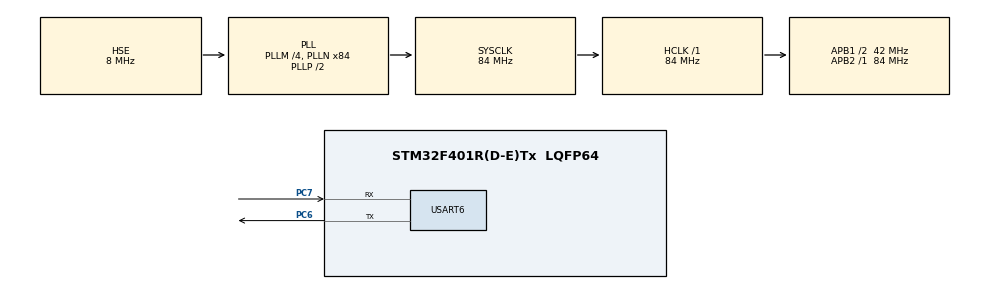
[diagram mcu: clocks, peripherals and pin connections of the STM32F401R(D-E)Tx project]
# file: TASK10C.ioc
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Mcu.Family=STM32F4
Mcu.Name=STM32F401R(D-E)Tx
Mcu.Package=LQFP64
NVIC.PriorityGroup=NVIC_PRIORITYGROUP_4
PC6.Mode=Asynchronous
PC6.Signal=USART6_TX
PC7.Mode=Asynchronous
PC7.Signal=USART6_RX
PH0\ -\ OSC_IN.Mode=HSE-External-Clock-Source
PH0\ -\ OSC_IN.Signal=RCC_OSC_IN
PH1\ -\ OSC_OUT.Mode=HSE-External-Clock-Source
PH1\ -\ OSC_OUT.Signal=RCC_OSC_OUT
ProjectManager.HeapSize=0x200
ProjectManager.StackSize=0x400
ProjectManager.TargetToolchain=MDK-ARM V5.32
RCC.48MHZClocksFreq_Value=42000000
RCC.AHBFreq_Value=84000000
RCC.APB1CLKDivider=RCC_HCLK_DIV2
RCC.APB1Freq_Value=42000000
RCC.APB1TimFreq_Value=84000000
RCC.APB2Freq_Value=84000000
RCC.APB2TimFreq_Value=84000000
RCC.CortexFreq_Value=84000000
RCC.HCLKFreq_Value=84000000
RCC.HSE_VALUE=8000000
RCC.HSI_VALUE=16000000
RCC.LSE_VALUE=32768
RCC.PLLM=4
RCC.PLLN=84
RCC.PLLSourceVirtual=RCC_PLLSOURCE_HSE
RCC.SYSCLKFreq_VALUE=84000000
RCC.SYSCLKSource=RCC_SYSCLKSOURCE_PLLCLK
RCC.VCOOutputFreq_Value=168000000
USART6.VirtualMode=VM_ASYNC
board=custom

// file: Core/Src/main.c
/* USER CODE BEGIN Header */
/**
  ******************************************************************************
  * @file           : main.c
  * @brief          : Main program body
  ******************************************************************************
  * @attention
  *
  * Copyright (c) 2026 STMicroelectronics.
  * All rights reserved.
  *
  * This software is licensed under terms that can be found in the LICENSE file
  * in the root directory of this software component.
  * If no LICENSE file comes with this software, it is provided AS-IS.
  *
  ******************************************************************************
  */
/* USER CODE END Header */
#include "main.h"
#include <stdio.h>
#include <string.h>
#include <stdlib.h>

UART_HandleTypeDef huart6;

void SystemClock_Config(void);
static void MX_GPIO_Init(void);
static void MX_USART6_UART_Init(void);

int main(void)
{

  /* MCU Configuration--------------------------------------------------------*/

  /* Reset of all peripherals, Initializes the Flash interface and the Systick. */
  HAL_Init();

  /* Configure the system clock */
  SystemClock_Config();

  /* Initialize all configured peripherals */
  MX_GPIO_Init();
  MX_USART6_UART_Init();
  /* USER CODE BEGIN 2 */
	uint8_t rx[513];
    uint16_t rxLen = 0;

    uint8_t cmd2[] = "AT\r\n";
    HAL_UART_Transmit(&huart6, cmd2, sizeof(cmd2)-1, 2000);
    HAL_UARTEx_ReceiveToIdle(&huart6, rx, 512, &rxLen, 5000);

    HAL_Delay(2000);

    uint8_t cmd3[] = "AT+CWMODE=1\r\n";
    HAL_UART_Transmit(&huart6, cmd3, sizeof(cmd3)-1, 2000);
    HAL_UARTEx_ReceiveToIdle(&huart6, rx, 512, &rxLen, 5000);

    HAL_Delay(2000);

    uint8_t cmd4[] = "AT+CWLAP\r\n";
    HAL_UART_Transmit(&huart6, cmd4, sizeof(cmd4)-1, 2000);
    HAL_UARTEx_ReceiveToIdle(&huart6, rx, 512, &rxLen, 10000);

    HAL_Delay(10000);

    uint8_t cmd5[] = "AT+CWJAP=\"SNUC\",\"snu12345\"\r\n";
    HAL_UART_Transmit(&huart6, cmd5, sizeof(cmd5)-1, 2000);
    HAL_UARTEx_ReceiveToIdle(&huart6, rx, 512, &rxLen, 15000);

    HAL_Delay(5000);

    uint8_t cmd6[] = "AT+CIFSR\r\n";
    HAL_UART_Transmit(&huart6, cmd6, sizeof(cmd6)-1, 2000);
    HAL_UARTEx_ReceiveToIdle(&huart6, rx, 512, &rxLen, 5000);

    HAL_Delay(5000);

  /* USER CODE END 2 */

  /* Infinite loop */
  /* USER CODE BEGIN WHILE */
  while(1)
	{

	}
  /* USER CODE END 3 */
}

void SystemClock_Config(void)
{
  RCC_OscInitTypeDef RCC_OscInitStruct = {0};
  RCC_ClkInitTypeDef RCC_ClkInitStruct = {0};

  /** Configure the main internal regulator output voltage
  */
  __HAL_RCC_PWR_CLK_ENABLE();
  __HAL_PWR_VOLTAGESCALING_CONFIG(PWR_REGULATOR_VOLTAGE_SCALE2);

  /** Initializes the RCC Oscillators according to the specified parameters
  * in the RCC_OscInitTypeDef structure.
  */
  RCC_OscInitStruct.OscillatorType = RCC_OSCILLATORTYPE_HSE;
  RCC_OscInitStruct.HSEState = RCC_HSE_BYPASS;
  RCC_OscInitStruct.PLL.PLLState = RCC_PLL_ON;
  RCC_OscInitStruct.PLL.PLLSource = RCC_PLLSOURCE_HSE;
  RCC_OscInitStruct.PLL.PLLM = 4;
  RCC_OscInitStruct.PLL.PLLN = 84;
  RCC_OscInitStruct.PLL.PLLP = RCC_PLLP_DIV2;
  RCC_OscInitStruct.PLL.PLLQ = 4;
  if (HAL_RCC_OscConfig(&RCC_OscInitStruct) != HAL_OK)
  {
    Error_Handler();
  }

  /** Initializes the CPU, AHB and APB buses clocks
  */
  RCC_ClkInitStruct.ClockType = RCC_CLOCKTYPE_HCLK|RCC_CLOCKTYPE_SYSCLK
                              |RCC_CLOCKTYPE_PCLK1|RCC_CLOCKTYPE_PCLK2;
  RCC_ClkInitStruct.SYSCLKSource = RCC_SYSCLKSOURCE_PLLCLK;
  RCC_ClkInitStruct.AHBCLKDivider = RCC_SYSCLK_DIV1;
  RCC_ClkInitStruct.APB1CLKDivider = RCC_HCLK_DIV2;
  RCC_ClkInitStruct.APB2CLKDivider = RCC_HCLK_DIV1;

  if (HAL_RCC_ClockConfig(&RCC_ClkInitStruct, FLASH_LATENCY_2) != HAL_OK)
  {
    Error_Handler();
  }
}

static void MX_USART6_UART_Init(void)
{

  huart6.Instance = USART6;
  huart6.Init.BaudRate = 115200;
  huart6.Init.WordLength = UART_WORDLENGTH_8B;
  huart6.Init.StopBits = UART_STOPBITS_1;
  huart6.Init.Parity = UART_PARITY_NONE;
  huart6.Init.Mode = UART_MODE_TX_RX;
  huart6.Init.HwFlowCtl = UART_HWCONTROL_NONE;
  huart6.Init.OverSampling = UART_OVERSAMPLING_16;
  if (HAL_UART_Init(&huart6) != HAL_OK)
  {
    Error_Handler();
  }

}

static void MX_GPIO_Init(void)
{

  /* GPIO Ports Clock Enable */
  __HAL_RCC_GPIOH_CLK_ENABLE();
  __HAL_RCC_GPIOC_CLK_ENABLE();

}

void Error_Handler(void)
{
  __disable_irq();
  while (1)
  {
  }
}
